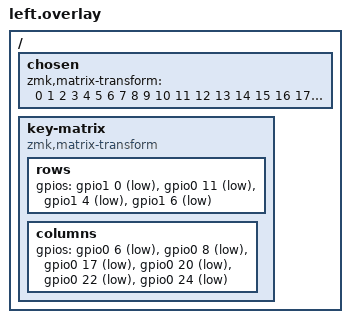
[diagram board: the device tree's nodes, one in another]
/ {
    chosen {
        zmk,matrix-transform = < 0  1  2  3  4  5
                                 6  7  8  9  10 11
                                 12 13 14 15 16 17
                                 18 19 20 21 22 23 >;
    };

    key-matrix {
        compatible = "zmk,matrix-transform";

        rows {
            gpios = <&gpio1 0 GPIO_ACTIVE_LOW>,   // Row 0 -> P1.00
                    <&gpio0 11 GPIO_ACTIVE_LOW>,  // Row 1 -> P0.11
                    <&gpio1 4 GPIO_ACTIVE_LOW>,   // Row 2 -> P1.04
                    <&gpio1 6 GPIO_ACTIVE_LOW>;   // Row 3 -> P1.06
        };

        columns {
            gpios = <&gpio0 6 GPIO_ACTIVE_LOW>,   // Column 0 -> P0.06
                    <&gpio0 8 GPIO_ACTIVE_LOW>,   // Column 1 -> P0.08
                    <&gpio0 17 GPIO_ACTIVE_LOW>,  // Column 2 -> P0.17
                    <&gpio0 20 GPIO_ACTIVE_LOW>,  // Column 3 -> P0.20
                    <&gpio0 22 GPIO_ACTIVE_LOW>,  // Column 4 -> P0.22
                    <&gpio0 24 GPIO_ACTIVE_LOW>;  // Column 5 -> P0.24
        };
    };
};
